# MCXN947_cm33_core0 register map
Vendor: nxp.com; File version: 1.0
CPU: CM33 r2p0, little endian, MPU, FPU, VTOR, 3 interrupt priority bits
Registers are 32-bit, read-write, reset 0x0 unless marked. A register's access mark holds for its fields unless they carry their own. Offsets are from the block's base; [hi:lo] are bit positions; {n}, {i} and the like mark numbered series.

## USBDCD0 — USBDCD
Base 0x400DC000
Same registers: USBHS1_PHY_DCD 0x4010A800
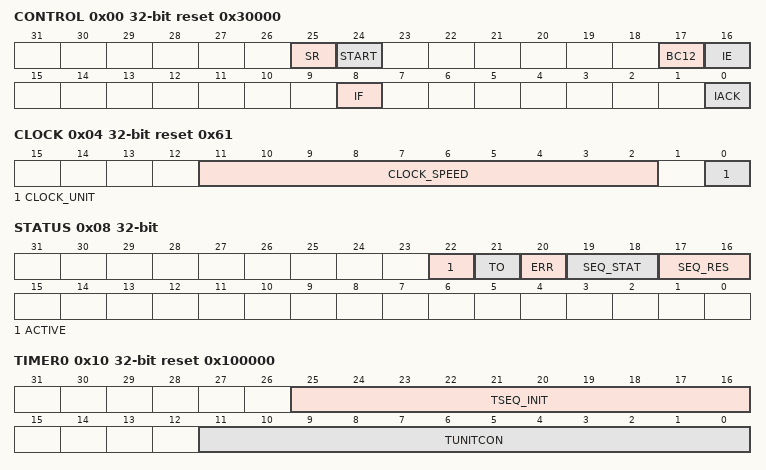
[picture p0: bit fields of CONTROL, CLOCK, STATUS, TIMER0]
0x00 CONTROL reset 0x30000
  [25] SR — Software Reset
    0=NO_RESET (Do not perform a software reset.); 1=SW_RESET (Perform a software reset.)
  [24] START — Start Change Detection Sequence
    0=NO_START (Do not start the sequence. Writes of this value have no effect.); 1=START (Initiate the charger detection sequence. If the sequence is already running, writes of this value have no effect.)
  [17] BC12 — Battery Charging Revision 1.2 Compatibility
    0=BC11 (Compatible with BC1.1); 1=BC12 (Compatible with BC1.2 (default))
  [16] IE — Interrupt Enable
    0=DIS_INT (Disable interrupts to the system.); 1=EN_INT (Enable interrupts to the system.)
  [8] IF ro — Interrupt Flag
    0=INT_PEND (No interrupt is pending.); 1=INT_NOPEND (An interrupt is pending.)
  [0] IACK — Interrupt Acknowledge
    0=INT_NOCLEAR (Do not clear the interrupt.); 1=INT_CLEAR (Clear the IF field (interrupt flag).)
0x04 CLOCK reset 0x61
  [11:2] CLOCK_SPEED — Numerical Value of Clock Speed in Binary
  [0] CLOCK_UNIT — Unit of Measurement Encoding for Clock Speed
    0=KHZ_CLK (kHz Speed (between 4 kHz and 1023 kHz)); 1=MHZ_CLK (MHz Speed (between 1 MHz and 1023 MHz))
0x08 STATUS ro
  [22] ACTIVE — Active Status Indicator
    0=SEQ_NOT_RUNNING (The sequence is not running.); 1=SEQ_RUNNING (The sequence is running.)
  [21] TO — Timeout Flag
    0=NO_TIMEOUT (The detection sequence is not running for over 1 s.); 1=TIMEOUT (It is over 1 s since the data pin contact was detected and debounced.)
  [20] ERR — Error Flag
    0=NO_SEQ_ERR (No sequence errors.); 1=SEQ_ERR (Error in the detection sequence.)
  [19:18] SEQ_STAT — Charger Detection Sequence Status
    0=NO_DATA_PIN_CONN (The module is either not enabled, or the module is enabled but the data pins have not yet been detected.); 1=DATA_PIN_CONN (Data pin contact detection is complete.); 2=CP_DET_DONE (Charging port detection is complete.); 3=CT_DET_DONE (Charger type detection is complete.)
  [17:16] SEQ_RES — Charger Detection Sequence Results
    0=NO_RESULT (No results to report.); 1=CONN_SDP (Attached to an SDP. Must comply with USB 2.0 by drawing only 2.5 mA (max) until connected.); 2=CONN_CP (Attached to a charging port. The exact meaning depends on the STATUS[SEQ_STAT] field (value 0: Attached to either a CDP or a DCP. The charger type detection has not completed. value 1: Attached to a CDP. The charger type detection has completed.)); 3=CONN_DCP (Attached to a DCP.)
0x0C SIGNAL_OVERRIDE
  [2:0] PS — Phase Selection
    0=NO_OVERRIDE (No overrides. Field must remain at this value during normal USB data communication to prevent unexpected conditions on USB_DP and USB_DM pins. (Default)); 2=PRI_DET_OVERRIDE (Enables VDP_SRC voltage source for the USB_DP pin and IDM_SINK current source for the USB_DM pin.); 4=CDP_ADVERT (Enables VDM_SRC voltage source only.)
0x10 TIMER0 reset 0x100000
  [25:16] TSEQ_INIT — Sequence Initiation Time
    {v}=MS_{v} (0 ms - 1023 ms) (v=0..9)
  [11:0] TUNITCON ro — Unit Connection Timer Elapse (in ms)
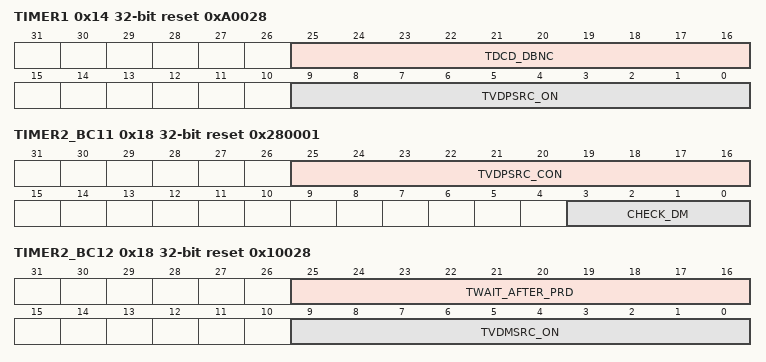
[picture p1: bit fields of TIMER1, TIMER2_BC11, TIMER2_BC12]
0x14 TIMER1 reset 0xA0028
  [25:16] TDCD_DBNC — Time Period to Debounce D+ Signal
    {v}=MS_{v} (1 ms - 1023 ms) (v=1..10)
  [9:0] TVDPSRC_ON — Time Period Comparator Enabled
    {v}=MS_{v} (1 ms - 1023 ms) (v=1..10)
0x18 TIMER2_BC11 reset 0x280001 (TIMER2 view)
  [25:16] TVDPSRC_CON — Time Period Before Enabling D+ Pullup
    {v}=MS_{v} (1 ms - 1023 ms) (v=1..10)
  [3:0] CHECK_DM — Time Before Check of D- Line
    {v}=MS_{v} (1 ms - 15 ms) (v=1..10)
0x18 TIMER2_BC12 reset 0x10028 (TIMER2 view)
  [25:16] TWAIT_AFTER_PRD
    {v}=MS_{v} (1 ms - 1023 ms) (v=1..10)
  [9:0] TVDMSRC_ON
    {v}=MS_{v} (0 ms - 40 ms) (v=0..9)
